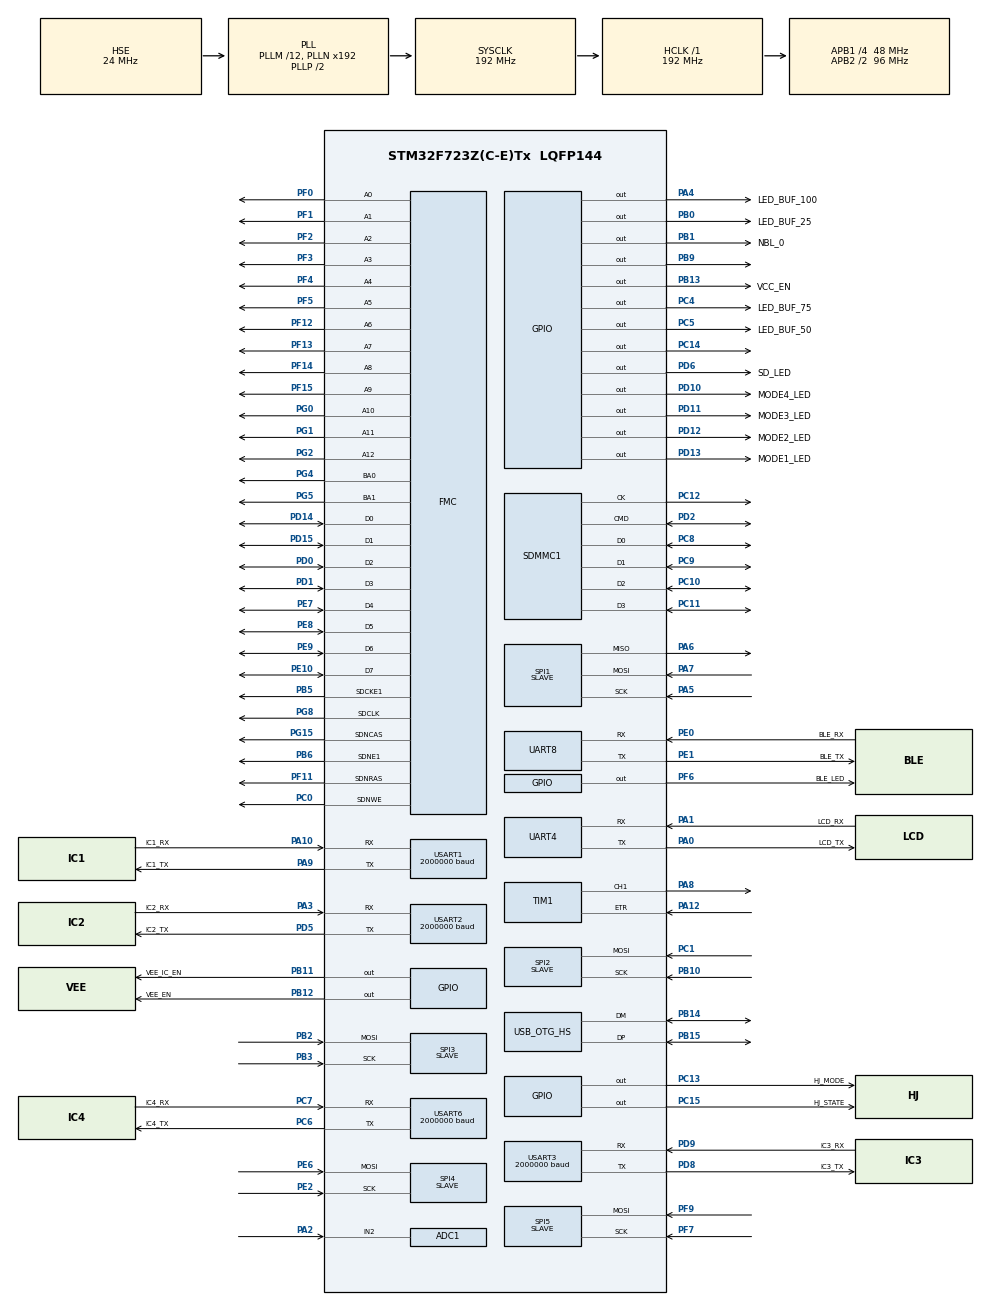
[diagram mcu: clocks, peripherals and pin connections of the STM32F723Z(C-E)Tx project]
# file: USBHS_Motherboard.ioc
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ADC1.Channel-0\#ChannelRegularConversion=ADC_CHANNEL_2
ADC1.ClockPrescaler=ADC_CLOCK_SYNC_PCLK_DIV4
ADC1.ContinuousConvMode=ENABLE
ADC1.DMAContinuousRequests=ENABLE
ADC1.DataAlign=ADC_DATAALIGN_LEFT
ADC1.EOCSelection=ADC_EOC_SINGLE_CONV
ADC1.ExternalTrigConv=ADC_SOFTWARE_START
ADC1.Mode=ADC_TRIPLEMODE_INTERL
ADC1.NbrOfConversion=1
ADC1.NbrOfConversionFlag=1
ADC1.Rank-0\#ChannelRegularConversion=1
ADC1.SamplingTime-0\#ChannelRegularConversion=ADC_SAMPLETIME_3CYCLES
ADC1.TwoSamplingDelay=ADC_TWOSAMPLINGDELAY_6CYCLES
ADC1.master=1
ADC2.Channel-0\#ChannelRegularConversion=ADC_CHANNEL_2
ADC2.ContinuousConvMode=DISABLE
ADC2.DMAAccessMode=ADC_DMAACCESSMODE_2
ADC2.DataAlign=ADC_DATAALIGN_LEFT
ADC2.Mode=ADC_TRIPLEMODE_INTERL
ADC2.NbrOfConversionFlag=1
ADC2.Rank-0\#ChannelRegularConversion=1
ADC2.SamplingTime-0\#ChannelRegularConversion=ADC_SAMPLETIME_3CYCLES
ADC2.TwoSamplingDelay=ADC_TWOSAMPLINGDELAY_6CYCLES
ADC3.Channel-0\#ChannelRegularConversion=ADC_CHANNEL_2
ADC3.ContinuousConvMode=DISABLE
ADC3.DMAAccessMode=ADC_DMAACCESSMODE_2
ADC3.DataAlign=ADC_DATAALIGN_LEFT
ADC3.Mode=ADC_TRIPLEMODE_INTERL
ADC3.NbrOfConversionFlag=1
ADC3.Rank-0\#ChannelRegularConversion=1
ADC3.SamplingTime-0\#ChannelRegularConversion=ADC_SAMPLETIME_3CYCLES
ADC3.TwoSamplingDelay=ADC_TWOSAMPLINGDELAY_6CYCLES
CORTEX_M7.ART_ACCLERATOR_ENABLE=0
CORTEX_M7.CPU_DCache=Enabled
CORTEX_M7.CPU_ICache=Enabled
CORTEX_M7.PREFETCH_ENABLE=1
Dma.ADC1.4.Direction=DMA_PERIPH_TO_MEMORY
Dma.ADC1.4.FIFOMode=DMA_FIFOMODE_ENABLE
Dma.ADC1.4.FIFOThreshold=DMA_FIFO_THRESHOLD_1QUARTERFULL
Dma.ADC1.4.Instance=DMA2_Stream0
Dma.ADC1.4.MemBurst=DMA_MBURST_SINGLE
Dma.ADC1.4.MemDataAlignment=DMA_MDATAALIGN_WORD
Dma.ADC1.4.MemInc=DMA_MINC_ENABLE
Dma.ADC1.4.Mode=DMA_CIRCULAR
Dma.ADC1.4.PeriphBurst=DMA_PBURST_SINGLE
Dma.ADC1.4.PeriphDataAlignment=DMA_PDATAALIGN_WORD
Dma.ADC1.4.PeriphInc=DMA_PINC_DISABLE
Dma.ADC1.4.Priority=DMA_PRIORITY_VERY_HIGH
Dma.Request0=USART1_RX
Dma.Request1=USART2_RX
Dma.Request2=USART3_RX
Dma.Request3=USART6_RX
Dma.Request4=ADC1
Dma.USART1_RX.0.Direction=DMA_PERIPH_TO_MEMORY
Dma.USART1_RX.0.FIFOMode=DMA_FIFOMODE_ENABLE
Dma.USART1_RX.0.FIFOThreshold=DMA_FIFO_THRESHOLD_HALFFULL
Dma.USART1_RX.0.Instance=DMA2_Stream2
Dma.USART1_RX.0.MemBurst=DMA_MBURST_SINGLE
Dma.USART1_RX.0.MemDataAlignment=DMA_MDATAALIGN_WORD
Dma.USART1_RX.0.MemInc=DMA_MINC_ENABLE
Dma.USART1_RX.0.Mode=DMA_NORMAL
Dma.USART1_RX.0.PeriphBurst=DMA_PBURST_SINGLE
Dma.USART1_RX.0.PeriphDataAlignment=DMA_PDATAALIGN_BYTE
Dma.USART1_RX.0.PeriphInc=DMA_PINC_DISABLE
Dma.USART1_RX.0.Priority=DMA_PRIORITY_MEDIUM
Dma.USART2_RX.1.Direction=DMA_PERIPH_TO_MEMORY
Dma.USART2_RX.1.FIFOMode=DMA_FIFOMODE_DISABLE
Dma.USART2_RX.1.Instance=DMA1_Stream5
Dma.USART2_RX.1.MemDataAlignment=DMA_MDATAALIGN_BYTE
Dma.USART2_RX.1.MemInc=DMA_MINC_ENABLE
Dma.USART2_RX.1.Mode=DMA_NORMAL
Dma.USART2_RX.1.PeriphDataAlignment=DMA_PDATAALIGN_BYTE
Dma.USART2_RX.1.PeriphInc=DMA_PINC_DISABLE
Dma.USART2_RX.1.Priority=DMA_PRIORITY_VERY_HIGH
Dma.USART3_RX.2.Direction=DMA_PERIPH_TO_MEMORY
Dma.USART3_RX.2.FIFOMode=DMA_FIFOMODE_ENABLE
Dma.USART3_RX.2.FIFOThreshold=DMA_FIFO_THRESHOLD_HALFFULL
Dma.USART3_RX.2.Instance=DMA1_Stream1
Dma.USART3_RX.2.MemBurst=DMA_MBURST_SINGLE
Dma.USART3_RX.2.MemDataAlignment=DMA_MDATAALIGN_WORD
Dma.USART3_RX.2.MemInc=DMA_MINC_ENABLE
Dma.USART3_RX.2.Mode=DMA_NORMAL
Dma.USART3_RX.2.PeriphBurst=DMA_PBURST_SINGLE
Dma.USART3_RX.2.PeriphDataAlignment=DMA_PDATAALIGN_WORD
Dma.USART3_RX.2.PeriphInc=DMA_PINC_DISABLE
Dma.USART3_RX.2.Priority=DMA_PRIORITY_LOW
Dma.USART6_RX.3.Direction=DMA_PERIPH_TO_MEMORY
Dma.USART6_RX.3.FIFOMode=DMA_FIFOMODE_ENABLE
Dma.USART6_RX.3.FIFOThreshold=DMA_FIFO_THRESHOLD_HALFFULL
Dma.USART6_RX.3.Instance=DMA2_Stream1
Dma.USART6_RX.3.MemBurst=DMA_MBURST_SINGLE
Dma.USART6_RX.3.MemDataAlignment=DMA_MDATAALIGN_WORD
Dma.USART6_RX.3.MemInc=DMA_MINC_ENABLE
Dma.USART6_RX.3.Mode=DMA_NORMAL
Dma.USART6_RX.3.PeriphBurst=DMA_PBURST_SINGLE
Dma.USART6_RX.3.PeriphDataAlignment=DMA_PDATAALIGN_WORD
Dma.USART6_RX.3.PeriphInc=DMA_PINC_DISABLE
Dma.USART6_RX.3.Priority=DMA_PRIORITY_LOW
FMC.CASLatency1=FMC_SDRAM_CAS_LATENCY_2
FMC.ColumnBitsNumber1=FMC_SDRAM_COLUMN_BITS_NUM_10
FMC.WriteProtection1=FMC_SDRAM_WRITE_PROTECTION_DISABLE
Mcu.Family=STM32F7
Mcu.Name=STM32F723Z(C-E)Tx
Mcu.Package=LQFP144
NVIC.DMA1_Stream1_IRQn=true\:1\:0\:true\:false\:true\:false\:false
NVIC.DMA1_Stream5_IRQn=true\:2\:0\:true\:false\:true\:false\:false
NVIC.DMA2_Stream0_IRQn=true\:2\:0\:true\:false\:true\:false\:false
NVIC.DMA2_Stream1_IRQn=true\:3\:0\:true\:false\:true\:false\:false
NVIC.DMA2_Stream2_IRQn=true\:4\:0\:true\:false\:true\:false\:false
NVIC.OTG_HS_IRQn=true\:5\:0\:true\:false\:true\:false\:true
NVIC.PriorityGroup=NVIC_PRIORITYGROUP_4
NVIC.SDMMC1_IRQn=true\:9\:0\:true\:false\:true\:true\:false
NVIC.TIM8_TRG_COM_TIM14_IRQn=true\:6\:0\:true\:false\:true\:true\:false
NVIC.UART4_IRQn=true\:11\:0\:true\:false\:true\:true\:false
NVIC.UART8_IRQn=true\:15\:0\:true\:false\:true\:true\:false
NVIC.USART1_IRQn=true\:12\:0\:true\:false\:true\:true\:false
NVIC.USART2_IRQn=true\:13\:0\:true\:false\:true\:true\:false
NVIC.USART3_IRQn=true\:14\:0\:true\:false\:true\:true\:false
NVIC.USART6_IRQn=true\:10\:0\:true\:false\:true\:true\:false
PA0-WKUP.GPIO_Label=LCD_TX
PA0-WKUP.Mode=Asynchronous
PA0-WKUP.Signal=UART4_TX
PA1.GPIO_Label=LCD_RX
PA1.Mode=Asynchronous
PA1.Signal=UART4_RX
PA10.GPIO_Label=IC1_RX
PA10.Mode=Asynchronous
PA10.Signal=USART1_RX
PA12.Signal=S_TIM1_ETR
PA13.Mode=Serial_Wire
PA13.Signal=SYS_JTMS-SWDIO
PA14.Mode=Serial_Wire
PA14.Signal=SYS_JTCK-SWCLK
PA2.Signal=ADCx_IN2
PA3.GPIO_Label=IC2_RX
PA3.Mode=Asynchronous
PA3.Signal=USART2_RX
PA4.GPIO_Label=LED_BUF_100
PA4.Signal=GPIO_Output
PA5.Mode=Full_Duplex_Slave
PA5.Signal=SPI1_SCK
PA6.Mode=Full_Duplex_Slave
PA6.Signal=SPI1_MISO
PA7.Mode=Full_Duplex_Slave
PA7.Signal=SPI1_MOSI
PA8.Signal=S_TIM1_CH1
PA9.GPIO_Label=IC1_TX
PA9.Mode=Asynchronous
PA9.Signal=USART1_TX
PB0.GPIO_Label=LED_BUF_25
PB0.Signal=GPIO_Output
PB1.GPIO_Label=NBL_0
PB1.GPIO_Speed=GPIO_SPEED_FREQ_VERY_HIGH
PB1.PinState=GPIO_PIN_SET
PB1.Signal=GPIO_Output
PB10.Mode=RX_Only_Simplex_Unidirect_Slave
PB10.Signal=SPI2_SCK
PB11.GPIO_Label=VEE_IC_EN
PB11.Signal=GPIO_Output
PB12.GPIO_Label=VEE_EN
PB12.Signal=GPIO_Output
PB13.GPIO_Label=VCC_EN
PB13.Signal=GPIO_Output
PB14.Mode=Internal_Phy_Device
PB14.Signal=USB_OTG_HS_DM
PB15.Mode=Internal_Phy_Device
PB15.Signal=USB_OTG_HS_DP
PB2.Mode=RX_Only_Simplex_Unidirect_Slave
PB2.Signal=SPI3_MOSI
PB3.Mode=RX_Only_Simplex_Unidirect_Slave
PB3.Signal=SPI3_SCK
PB5.Mode=SdramChipSelect2_1
PB5.Signal=FMC_SDCKE1
PB6.Mode=SdramChipSelect2_1
PB6.Signal=FMC_SDNE1
PB9.Signal=GPIO_Output
PC0.Signal=FMC_SDNWE
PC1.Mode=RX_Only_Simplex_Unidirect_Slave
PC1.Signal=SPI2_MOSI
PC10.Mode=SD_4_bits_Wide_bus
PC10.Signal=SDMMC1_D2
PC11.Mode=SD_4_bits_Wide_bus
PC11.Signal=SDMMC1_D3
PC12.Mode=SD_4_bits_Wide_bus
PC12.Signal=SDMMC1_CK
PC13.GPIO_Label=HJ_MODE
PC13.Signal=GPIO_Output
PC14-OSC32_IN.Signal=GPIO_Output
PC15-OSC32_OUT.GPIO_Label=HJ_STATE
PC15-OSC32_OUT.Signal=GPIO_Output
PC4.GPIO_Label=LED_BUF_75
PC4.Signal=GPIO_Output
PC5.GPIO_Label=LED_BUF_50
PC5.Signal=GPIO_Output
PC6.GPIO_Label=IC4_TX
PC6.Mode=Asynchronous
PC6.Signal=USART6_TX
PC7.GPIO_Label=IC4_RX
PC7.Mode=Asynchronous
PC7.Signal=USART6_RX
PC8.Mode=SD_4_bits_Wide_bus
PC8.Signal=SDMMC1_D0
PC9.Mode=SD_4_bits_Wide_bus
PC9.Signal=SDMMC1_D1
PD0.Signal=FMC_D2_DA2
PD1.Signal=FMC_D3_DA3
PD10.GPIO_Label=MODE4_LED
PD10.Signal=GPIO_Output
PD11.GPIO_Label=MODE3_LED
PD11.Signal=GPIO_Output
PD12.GPIO_Label=MODE2_LED
PD12.Signal=GPIO_Output
PD13.GPIO_Label=MODE1_LED
PD13.Signal=GPIO_Output
PD14.Signal=FMC_D0_DA0
PD15.Signal=FMC_D1_DA1
PD2.Mode=SD_4_bits_Wide_bus
PD2.Signal=SDMMC1_CMD
PD5.GPIO_Label=IC2_TX
PD5.Mode=Asynchronous
PD5.Signal=USART2_TX
PD6.GPIO_Label=SD_LED
PD6.Signal=GPIO_Output
PD8.GPIO_Label=IC3_TX
PD8.Mode=Asynchronous
PD8.Signal=USART3_TX
PD9.GPIO_Label=IC3_RX
PD9.Mode=Asynchronous
PD9.Signal=USART3_RX
PE0.GPIO_Label=BLE_RX
PE0.Mode=Asynchronous
PE0.Signal=UART8_RX
PE1.GPIO_Label=BLE_TX
PE1.Mode=Asynchronous
PE1.Signal=UART8_TX
PE10.Signal=FMC_D7_DA7
PE2.Mode=RX_Only_Simplex_Unidirect_Slave
PE2.Signal=SPI4_SCK
PE6.Mode=RX_Only_Simplex_Unidirect_Slave
PE6.Signal=SPI4_MOSI
PE7.Signal=FMC_D4_DA4
PE8.Signal=FMC_D5_DA5
PE9.Signal=FMC_D6_DA6
PF0.Signal=FMC_A0
PF1.Signal=FMC_A1
PF11.Signal=FMC_SDNRAS
PF12.Signal=FMC_A6
PF13.Signal=FMC_A7
PF14.Signal=FMC_A8
PF15.Signal=FMC_A9
PF2.Signal=FMC_A2
PF3.Signal=FMC_A3
PF4.Signal=FMC_A4
PF5.Signal=FMC_A5
PF6.GPIO_Label=BLE_LED
PF6.Signal=GPIO_Output
PF7.Mode=RX_Only_Simplex_Unidirect_Slave
PF7.Signal=SPI5_SCK
PF9.Mode=RX_Only_Simplex_Unidirect_Slave
PF9.Signal=SPI5_MOSI
PG0.Signal=FMC_A10
PG1.Signal=FMC_A11
PG15.Signal=FMC_SDNCAS
PG2.Signal=FMC_A12
PG4.Signal=FMC_A14_BA0
PG5.Signal=FMC_A15_BA1
PG8.Signal=FMC_SDCLK
PH0-OSC_IN.Mode=HSE-External-Oscillator
PH0-OSC_IN.Signal=RCC_OSC_IN
PH1-OSC_OUT.Mode=HSE-External-Oscillator
PH1-OSC_OUT.Signal=RCC_OSC_OUT
ProjectManager.HeapSize=0x2000
ProjectManager.StackSize=0x2000
ProjectManager.TargetToolchain=MDK-ARM V5
RCC.AHBFreq_Value=192000000
RCC.APB1CLKDivider=RCC_HCLK_DIV4
RCC.APB1Freq_Value=48000000
RCC.APB1TimFreq_Value=96000000
RCC.APB2CLKDivider=RCC_HCLK_DIV2
RCC.APB2Freq_Value=96000000
RCC.APB2TimFreq_Value=192000000
RCC.CortexFreq_Value=192000000
RCC.HCLKFreq_Value=192000000
RCC.HSE_VALUE=24000000
RCC.HSI_VALUE=16000000
RCC.LSE_VALUE=32768
RCC.PLLM=12
RCC.PLLQ=8
RCC.SDMMCClockSelection=RCC_SDMMC1CLKSOURCE_CLK48
RCC.SYSCLKFreq_VALUE=192000000
RCC.SYSCLKSource=RCC_SYSCLKSOURCE_PLLCLK
RCC.USBFreq_Value=48000000
RCC.VCOOutputFreq_Value=384000000
REXTPHYHS.Mode=Internal_Phy_Device
REXTPHYHS.Signal=USB_OTG_HS_REXTPHYHS
SH.ADCx_IN2.0=ADC1_IN2,IN2
SH.ADCx_IN2.1=ADC2_IN2,IN2
SH.ADCx_IN2.2=ADC3_IN2,IN2
SH.FMC_A0.0=FMC_A0,13b-sda1
SH.FMC_A1.0=FMC_A1,13b-sda1
SH.FMC_A10.0=FMC_A10,13b-sda1
SH.FMC_A11.0=FMC_A11,13b-sda1
SH.FMC_A12.0=FMC_A12,13b-sda1
SH.FMC_A14_BA0.0=FMC_BA0,FourSdramBanks1
SH.FMC_A15_BA1.0=FMC_BA1,FourSdramBanks1
SH.FMC_A2.0=FMC_A2,13b-sda1
SH.FMC_A3.0=FMC_A3,13b-sda1
SH.FMC_A4.0=FMC_A4,13b-sda1
SH.FMC_A5.0=FMC_A5,13b-sda1
SH.FMC_A6.0=FMC_A6,13b-sda1
SH.FMC_A7.0=FMC_A7,13b-sda1
SH.FMC_A8.0=FMC_A8,13b-sda1
SH.FMC_A9.0=FMC_A9,13b-sda1
SH.FMC_D0_DA0.0=FMC_D0,sd-8b-d1
SH.FMC_D1_DA1.0=FMC_D1,sd-8b-d1
SH.FMC_D2_DA2.0=FMC_D2,sd-8b-d1
SH.FMC_D3_DA3.0=FMC_D3,sd-8b-d1
SH.FMC_D4_DA4.0=FMC_D4,sd-8b-d1
SH.FMC_D5_DA5.0=FMC_D5,sd-8b-d1
SH.FMC_D6_DA6.0=FMC_D6,sd-8b-d1
SH.FMC_D7_DA7.0=FMC_D7,sd-8b-d1
SH.FMC_SDCLK.0=FMC_SDCLK,13b-sda1
SH.FMC_SDNCAS.0=FMC_SDNCAS,13b-sda1
SH.FMC_SDNRAS.0=FMC_SDNRAS,13b-sda1
SH.FMC_SDNWE.0=FMC_SDNWE,13b-sda1
SH.S_TIM1_CH1.0=TIM1_CH1,Output Compare1 CH1
SH.S_TIM1_ETR.0=TIM1_ETR,TriggerSource_ETR
SPI1.DataSize=SPI_DATASIZE_16BIT
SPI1.Direction=SPI_DIRECTION_2LINES
SPI1.Mode=SPI_MODE_SLAVE
SPI1.VirtualType=VM_SLAVE
SPI2.DataSize=SPI_DATASIZE_16BIT
SPI2.Direction=SPI_DIRECTION_2LINES_RXONLY
SPI2.Mode=SPI_MODE_SLAVE
SPI2.VirtualType=VM_SLAVE
SPI3.DataSize=SPI_DATASIZE_16BIT
SPI3.Direction=SPI_DIRECTION_2LINES_RXONLY
SPI3.Mode=SPI_MODE_SLAVE
SPI3.VirtualType=VM_SLAVE
SPI4.DataSize=SPI_DATASIZE_16BIT
SPI4.Direction=SPI_DIRECTION_2LINES_RXONLY
SPI4.Mode=SPI_MODE_SLAVE
SPI4.VirtualType=VM_SLAVE
SPI5.DataSize=SPI_DATASIZE_16BIT
SPI5.Direction=SPI_DIRECTION_2LINES_RXONLY
SPI5.Mode=SPI_MODE_SLAVE
SPI5.VirtualType=VM_SLAVE
TIM1.Channel-Output\ Compare1\ CH1=TIM_CHANNEL_1
TIM14.AutoReloadPreload=TIM_AUTORELOAD_PRELOAD_ENABLE
TIM14.Period=1999
TIM14.Prescaler=21599
TIM6.AutoReloadPreload=TIM_AUTORELOAD_PRELOAD_ENABLE
TIM6.Period=143
TIM6.Prescaler=0
TIM6.TIM_MasterOutputTrigger=TIM_TRGO_UPDATE
USART1.BaudRate=2000000
USART1.DMADisableonRxErrorParam=ADVFEATURE_DMA_ENABLEONRXERROR
USART1.OverSampling=UART_OVERSAMPLING_16
USART1.OverrunDisableParam=ADVFEATURE_OVERRUN_DISABLE
USART1.VirtualMode-Asynchronous=VM_ASYNC
USART2.BaudRate=2000000
USART2.DMADisableonRxErrorParam=ADVFEATURE_DMA_ENABLEONRXERROR
USART2.OverSampling=UART_OVERSAMPLING_16
USART2.OverrunDisableParam=ADVFEATURE_OVERRUN_DISABLE
USART2.VirtualMode-Asynchronous=VM_ASYNC
USART3.BaudRate=2000000
USART3.DMADisableonRxErrorParam=ADVFEATURE_DMA_ENABLEONRXERROR
USART3.OverSampling=UART_OVERSAMPLING_16
USART3.OverrunDisableParam=ADVFEATURE_OVERRUN_DISABLE
USART3.VirtualMode-Asynchronous=VM_ASYNC
USART6.BaudRate=2000000
USART6.DMADisableonRxErrorParam=ADVFEATURE_DMA_ENABLEONRXERROR
USART6.OverSampling=UART_OVERSAMPLING_16
USART6.OverrunDisableParam=ADVFEATURE_OVERRUN_DISABLE
USART6.VirtualMode-Asynchronous=VM_ASYNC
USB_DEVICE.CLASS_NAME_HS=CDC
USB_DEVICE.USBD_LPM_ENABLED-CDC_HS=0
USB_DEVICE.USBD_SELF_POWERED-CDC_HS=1
USB_DEVICE.VirtualMode-CDC_HS=Cdc
USB_DEVICE.VirtualModeHS=Cdc_HS
USB_OTG_HS.VirtualMode=Int_Phy_Device
VP_TIM14_VS_ClockSourceINT.Mode=Enable_Timer
VP_TIM1_VS_ClockSourceINT.Mode=Internal
VP_TIM1_VS_ControllerModeTrigger.Mode=Trigger Mode
VP_TIM6_VS_ClockSourceINT.Mode=Enable_Timer
VP_USB_DEVICE_VS_USB_DEVICE_CDC_HS.Mode=CDC_HS
board=custom

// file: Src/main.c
/* USER CODE BEGIN Header */
/**
  ******************************************************************************
  * @file           : main.c
  * @brief          : Main program body
  ******************************************************************************
  * @attention
  *
  * <h2><center>&copy; Copyright (c) 2020 STMicroelectronics.
  * All rights reserved.</center></h2>
  *
  * This software component is licensed by ST under Ultimate Liberty license
  * SLA0044, the "License"; You may not use this file except in compliance with
  * the License. You may obtain a copy of the License at:
  *                             www.st.com/SLA0044
  *
  ******************************************************************************
  */
/* USER CODE END Header */

#include "main.h"
#include "usb_device.h"

/* USER CODE BEGIN Includes */
#include "dataMGR.h"
#include "CE32_ioncom.h"
#include "usbd_cdc_if.h"

/* USER CODE END Includes */

ADC_HandleTypeDef hadc1;
ADC_HandleTypeDef hadc2;
ADC_HandleTypeDef hadc3;
DMA_HandleTypeDef hdma_adc1;

SD_HandleTypeDef hsd1;

SPI_HandleTypeDef hspi1;
SPI_HandleTypeDef hspi2;
SPI_HandleTypeDef hspi3;
SPI_HandleTypeDef hspi4;
SPI_HandleTypeDef hspi5;

TIM_HandleTypeDef htim1;
TIM_HandleTypeDef htim6;
TIM_HandleTypeDef htim14;

UART_HandleTypeDef huart4;
UART_HandleTypeDef huart8;
UART_HandleTypeDef huart1;
UART_HandleTypeDef huart2;
UART_HandleTypeDef huart3;
UART_HandleTypeDef huart6;
DMA_HandleTypeDef hdma_usart1_rx;
DMA_HandleTypeDef hdma_usart2_rx;
DMA_HandleTypeDef hdma_usart3_rx;
DMA_HandleTypeDef hdma_usart6_rx;

SDRAM_HandleTypeDef hsdram1;

/* USER CODE BEGIN PV */
int Nfail;
int retries;
int WaitCyc;
uint8_t data_buf_RX1[0x10];		// This records @ 20kHz x 32CH
uint8_t data_buf_RX2[0x10];		// This records @ 20kHz x 32CH
uint8_t data_buf_RX3[0x10];		// This records @ 20kHz x 32CH
uint8_t data_buf_RX4[0x10];		// This records @ 20kHz x 32CH
uint8_t data_buf_TX[0x100];		// This records @ 20kHz x 32CH
uint8_t data_buf_RX_CDC[BUF_SIZE];
uint16_t misc_DigiSig;
uint8_t rec_cnt;
uint32_t log_cnt;
uint32_t test;
uint32_t LED_CNT;
uint32_t logIdx;	//Index of log in the CE32_systemLog struct
uint32_t filePTR;	//recording pointer location (in 512B unit,real filelen=512*x)
uint32_t updHeader;
dataMGR MGR_TX;
dataMGR MGR_RX1;
dataMGR MGR_RX2;
dataMGR MGR_RX3;
dataMGR MGR_RX4;
dataMGR MGR_CDC;
dataMGR MGR_prev;
dataMGR MGR_misc;
dataMGR MGR_cmd;
uint8_t HD32_sd_temp;

//dataMGR PMGR;
int freq;

const uint16_t RX_size=1000;

CE32_IONCOM_Handle IC_handle1;
CE32_IONCOM_Handle IC_handle2;
CE32_IONCOM_Handle IC_handle3;
CE32_IONCOM_Handle IC_handle4;

extern USBD_HandleTypeDef hUsbDeviceFS;

/* USER CODE END PV */

void SystemClock_Config(void);
static void MX_GPIO_Init(void);
static void MX_DMA_Init(void);
static void MX_FMC_Init(void);
static void MX_SDMMC1_SD_Init(void);
static void MX_SPI1_Init(void);
static void MX_SPI2_Init(void);
static void MX_SPI3_Init(void);
static void MX_SPI4_Init(void);
static void MX_SPI5_Init(void);
static void MX_TIM1_Init(void);
static void MX_UART4_Init(void);
static void MX_UART8_Init(void);
static void MX_USART1_UART_Init(void);
static void MX_USART2_UART_Init(void);
static void MX_USART3_UART_Init(void);
static void MX_USART6_UART_Init(void);
static void MX_TIM14_Init(void);
static void MX_ADC1_Init(void);
static void MX_ADC2_Init(void);
static void MX_ADC3_Init(void);
static void MX_TIM6_Init(void);
/* USER CODE BEGIN PFP */

void PowerUp_IC();
void Init_Buffer();
void Init_Ioncom_Receiver();
void RXdata_Indicator_Init();
void RX_processor(CE32_IONCOM_Handle *IC_handle,int CH);
void USB_SEND();
/* USER CODE END PFP */

int main(void)
{

  /* Enable I-Cache---------------------------------------------------------*/
  SCB_EnableICache();

  /* Enable D-Cache---------------------------------------------------------*/
  SCB_EnableDCache();

  /* MCU Configuration--------------------------------------------------------*/

  /* Reset of all peripherals, Initializes the Flash interface and the Systick. */
  HAL_Init();

  /* Configure the system clock */
  SystemClock_Config();

  /* Initialize all configured peripherals */
  MX_GPIO_Init();
  MX_DMA_Init();
  MX_FMC_Init();
  MX_SDMMC1_SD_Init();
  MX_SPI1_Init();
  MX_SPI2_Init();
  MX_SPI3_Init();
  MX_SPI4_Init();
  MX_SPI5_Init();
  MX_TIM1_Init();
  MX_UART4_Init();
  MX_UART8_Init();
  MX_USART1_UART_Init();
  MX_USART2_UART_Init();
  MX_USART3_UART_Init();
  MX_USART6_UART_Init();
  MX_USB_DEVICE_Init();
  MX_TIM14_Init();
  MX_ADC1_Init();
  MX_ADC2_Init();
  MX_ADC3_Init();
  MX_TIM6_Init();
  /* USER CODE BEGIN 2 */
	//PowerUp_IC();
	//HAL_PWR_EnterSTOPMode(PWR_LOWPOWERREGULATOR_ON,PWR_STOPENTRY_WFI); //Enter STOP mode for debug
	Init_Buffer();
	//Init_Ioncom_Receiver();
	//MX_USB_DEVICE_Init();
	//RXdata_Indicator_Init();
	__HAL_ADC_ENABLE(&hadc1);
	__HAL_ADC_ENABLE(&hadc2);
	__HAL_ADC_ENABLE(&hadc3);
	uint32_t * ADC_test;
	//HAL_ADCEx_MultiModeStart_DMA(&hadc1,(uint32_t*)ADC_test,1);
	HAL_ADCEx_MultiModeStart_DMA(&hadc1,(uint32_t*)&data_buf_RX_CDC[3],(BUF_SIZE/4));
	__HAL_DMA_DISABLE_IT(hadc1.DMA_Handle,DMA_IT_TE); //disable interrupts other than half/full complete
	//__HAL_DMA_DISABLE_IT(hadc1.DMA_Handle,DMA_IT_FE);
	__HAL_DMA_DISABLE_IT(hadc1.DMA_Handle,DMA_IT_DME);
	hadc1.Instance->CR2 |= (uint32_t)ADC_CR2_SWSTART;
	//HAL_TIM_Base_Start(&htim6);// start timer for ADC
//	uint16_t x=0;
//	for(uint32_t i=0;i<BUF_SIZE/2;i++)
//	{
//		uint16_t* ptr =	(uint16_t*)data_buf_RX_CDC;
//		ptr[i] = 1000;
//	}
  /* USER CODE END 2 */

  /* Infinite loop */
  while (1)
  {

    /* USER CODE BEGIN 3 */
		//RX_processor(&IC_handle1,0);
		//RX_processor(&IC_handle2,1);
		//RX_processor(&IC_handle3,2);
		//RX_processor(&IC_handle4,3);
		HAL_GPIO_WritePin(LED_BUF_25_GPIO_Port,LED_BUF_25_Pin,MGR_CDC.bufferUsed[0]>(BUF_SIZE/4)?1:0);
		HAL_GPIO_WritePin(LED_BUF_50_GPIO_Port,LED_BUF_50_Pin,MGR_CDC.bufferUsed[0]>(BUF_SIZE/2)?1:0);
		HAL_GPIO_WritePin(LED_BUF_75_GPIO_Port,LED_BUF_75_Pin,MGR_CDC.bufferUsed[0]>(BUF_SIZE*3/4)?1:0);
		HAL_GPIO_WritePin(LED_BUF_100_GPIO_Port,LED_BUF_100_Pin,MGR_CDC.bufferUsed[0]>=BUF_SIZE?1:0);

		if(MGR_CDC.bufferUsed[0]>2*BUF_SIZE)
		{
			uint32_t purge_cnt=BUF_SIZE/2;
			dataMGR_deQueue(&MGR_CDC,purge_cnt,0); //clear buffer
		}
		USB_SEND();
//		if(MGR_CDC.bufferUsed[0]<BUF_SIZE/2)
//		{
//			dataMGR_enQueue_Nbytes(&MGR_CDC,BUF_SIZE/2);
//		}
  }
  /* USER CODE END 3 */
}

void SystemClock_Config(void)
{
  RCC_OscInitTypeDef RCC_OscInitStruct = {0};
  RCC_ClkInitTypeDef RCC_ClkInitStruct = {0};
  RCC_PeriphCLKInitTypeDef PeriphClkInitStruct = {0};

  /** Configure the main internal regulator output voltage
  */
  __HAL_RCC_PWR_CLK_ENABLE();
  __HAL_PWR_VOLTAGESCALING_CONFIG(PWR_REGULATOR_VOLTAGE_SCALE1);
  /** Initializes the CPU, AHB and APB busses clocks
  */
  RCC_OscInitStruct.OscillatorType = RCC_OSCILLATORTYPE_HSE;
  RCC_OscInitStruct.HSEState = RCC_HSE_ON;
  RCC_OscInitStruct.PLL.PLLState = RCC_PLL_ON;
  RCC_OscInitStruct.PLL.PLLSource = RCC_PLLSOURCE_HSE;
  RCC_OscInitStruct.PLL.PLLM = 12;
  RCC_OscInitStruct.PLL.PLLN = 192;
  RCC_OscInitStruct.PLL.PLLP = RCC_PLLP_DIV2;
  RCC_OscInitStruct.PLL.PLLQ = 8;
  if (HAL_RCC_OscConfig(&RCC_OscInitStruct) != HAL_OK)
  {
    Error_Handler();
  }
  /** Activate the Over-Drive mode
  */
  if (HAL_PWREx_EnableOverDrive() != HAL_OK)
  {
    Error_Handler();
  }
  /** Initializes the CPU, AHB and APB busses clocks
  */
  RCC_ClkInitStruct.ClockType = RCC_CLOCKTYPE_HCLK|RCC_CLOCKTYPE_SYSCLK
                              |RCC_CLOCKTYPE_PCLK1|RCC_CLOCKTYPE_PCLK2;
  RCC_ClkInitStruct.SYSCLKSource = RCC_SYSCLKSOURCE_PLLCLK;
  RCC_ClkInitStruct.AHBCLKDivider = RCC_SYSCLK_DIV1;
  RCC_ClkInitStruct.APB1CLKDivider = RCC_HCLK_DIV4;
  RCC_ClkInitStruct.APB2CLKDivider = RCC_HCLK_DIV2;

  if (HAL_RCC_ClockConfig(&RCC_ClkInitStruct, FLASH_LATENCY_6) != HAL_OK)
  {
    Error_Handler();
  }
  PeriphClkInitStruct.PeriphClockSelection = RCC_PERIPHCLK_USART1|RCC_PERIPHCLK_USART2
                              |RCC_PERIPHCLK_USART3|RCC_PERIPHCLK_USART6
                              |RCC_PERIPHCLK_UART4|RCC_PERIPHCLK_UART8
                              |RCC_PERIPHCLK_SDMMC1|RCC_PERIPHCLK_CLK48;
  PeriphClkInitStruct.Usart1ClockSelection = RCC_USART1CLKSOURCE_PCLK2;
  PeriphClkInitStruct.Usart2ClockSelection = RCC_USART2CLKSOURCE_PCLK1;
  PeriphClkInitStruct.Usart3ClockSelection = RCC_USART3CLKSOURCE_PCLK1;
  PeriphClkInitStruct.Uart4ClockSelection = RCC_UART4CLKSOURCE_PCLK1;
  PeriphClkInitStruct.Usart6ClockSelection = RCC_USART6CLKSOURCE_PCLK2;
  PeriphClkInitStruct.Uart8ClockSelection = RCC_UART8CLKSOURCE_PCLK1;
  PeriphClkInitStruct.Clk48ClockSelection = RCC_CLK48SOURCE_PLL;
  PeriphClkInitStruct.Sdmmc1ClockSelection = RCC_SDMMC1CLKSOURCE_CLK48;
  if (HAL_RCCEx_PeriphCLKConfig(&PeriphClkInitStruct) != HAL_OK)
  {
    Error_Handler();
  }
}

static void MX_ADC1_Init(void)
{

  ADC_MultiModeTypeDef multimode = {0};
  ADC_ChannelConfTypeDef sConfig = {0};

  /** Configure the global features of the ADC (Clock, Resolution, Data Alignment and number of conversion)
  */
  hadc1.Instance = ADC1;
  hadc1.Init.ClockPrescaler = ADC_CLOCK_SYNC_PCLK_DIV4;
  hadc1.Init.Resolution = ADC_RESOLUTION_12B;
  hadc1.Init.ScanConvMode = ADC_SCAN_DISABLE;
  hadc1.Init.ContinuousConvMode = ENABLE;
  hadc1.Init.DiscontinuousConvMode = DISABLE;
  hadc1.Init.ExternalTrigConvEdge = ADC_EXTERNALTRIGCONVEDGE_NONE;
  hadc1.Init.ExternalTrigConv = ADC_SOFTWARE_START;
  hadc1.Init.DataAlign = ADC_DATAALIGN_LEFT;
  hadc1.Init.NbrOfConversion = 1;
  hadc1.Init.DMAContinuousRequests = ENABLE;
  hadc1.Init.EOCSelection = ADC_EOC_SINGLE_CONV;
  if (HAL_ADC_Init(&hadc1) != HAL_OK)
  {
    Error_Handler();
  }
  /** Configure the ADC multi-mode
  */
  multimode.Mode = ADC_TRIPLEMODE_INTERL;
  multimode.DMAAccessMode = ADC_DMAACCESSMODE_2;
  multimode.TwoSamplingDelay = ADC_TWOSAMPLINGDELAY_6CYCLES;
  if (HAL_ADCEx_MultiModeConfigChannel(&hadc1, &multimode) != HAL_OK)
  {
    Error_Handler();
  }
  /** Configure for the selected ADC regular channel its corresponding rank in the sequencer and its sample time.
  */
  sConfig.Channel = ADC_CHANNEL_2;
  sConfig.Rank = ADC_REGULAR_RANK_1;
  sConfig.SamplingTime = ADC_SAMPLETIME_3CYCLES;
  if (HAL_ADC_ConfigChannel(&hadc1, &sConfig) != HAL_OK)
  {
    Error_Handler();
  }

}

static void MX_ADC2_Init(void)
{

  ADC_ChannelConfTypeDef sConfig = {0};

  /** Configure the global features of the ADC (Clock, Resolution, Data Alignment and number of conversion)
  */
  hadc2.Instance = ADC2;
  hadc2.Init.ClockPrescaler = ADC_CLOCK_SYNC_PCLK_DIV4;
  hadc2.Init.Resolution = ADC_RESOLUTION_12B;
  hadc2.Init.ScanConvMode = ADC_SCAN_DISABLE;
  hadc2.Init.ContinuousConvMode = DISABLE;
  hadc2.Init.DiscontinuousConvMode = DISABLE;
  hadc2.Init.DataAlign = ADC_DATAALIGN_LEFT;
  hadc2.Init.NbrOfConversion = 1;
  hadc2.Init.DMAContinuousRequests = DISABLE;
  hadc2.Init.EOCSelection = ADC_EOC_SINGLE_CONV;
  if (HAL_ADC_Init(&hadc2) != HAL_OK)
  {
    Error_Handler();
  }
  /** Configure for the selected ADC regular channel its corresponding rank in the sequencer and its sample time.
  */
  sConfig.Channel = ADC_CHANNEL_2;
  sConfig.Rank = ADC_REGULAR_RANK_1;
  sConfig.SamplingTime = ADC_SAMPLETIME_3CYCLES;
  if (HAL_ADC_ConfigChannel(&hadc2, &sConfig) != HAL_OK)
  {
    Error_Handler();
  }

}

static void MX_ADC3_Init(void)
{

  ADC_ChannelConfTypeDef sConfig = {0};

  /** Configure the global features of the ADC (Clock, Resolution, Data Alignment and number of conversion)
  */
  hadc3.Instance = ADC3;
  hadc3.Init.ClockPrescaler = ADC_CLOCK_SYNC_PCLK_DIV4;
  hadc3.Init.Resolution = ADC_RESOLUTION_12B;
  hadc3.Init.ScanConvMode = ADC_SCAN_DISABLE;
  hadc3.Init.ContinuousConvMode = DISABLE;
  hadc3.Init.DiscontinuousConvMode = DISABLE;
  hadc3.Init.DataAlign = ADC_DATAALIGN_LEFT;
  hadc3.Init.NbrOfConversion = 1;
  hadc3.Init.DMAContinuousRequests = DISABLE;
  hadc3.Init.EOCSelection = ADC_EOC_SINGLE_CONV;
  if (HAL_ADC_Init(&hadc3) != HAL_OK)
  {
    Error_Handler();
  }
  /** Configure for the selected ADC regular channel its corresponding rank in the sequencer and its sample time.
  */
  sConfig.Channel = ADC_CHANNEL_2;
  sConfig.Rank = ADC_REGULAR_RANK_1;
  sConfig.SamplingTime = ADC_SAMPLETIME_3CYCLES;
  if (HAL_ADC_ConfigChannel(&hadc3, &sConfig) != HAL_OK)
  {
    Error_Handler();
  }

}

static void MX_SDMMC1_SD_Init(void)
{

  hsd1.Instance = SDMMC1;
  hsd1.Init.ClockEdge = SDMMC_CLOCK_EDGE_RISING;
  hsd1.Init.ClockBypass = SDMMC_CLOCK_BYPASS_DISABLE;
  hsd1.Init.ClockPowerSave = SDMMC_CLOCK_POWER_SAVE_DISABLE;
  hsd1.Init.BusWide = SDMMC_BUS_WIDE_1B;
  hsd1.Init.HardwareFlowControl = SDMMC_HARDWARE_FLOW_CONTROL_DISABLE;
  hsd1.Init.ClockDiv = 0;
  if (HAL_SD_Init(&hsd1) != HAL_OK)
  {
    Error_Handler();
  }
  if (HAL_SD_ConfigWideBusOperation(&hsd1, SDMMC_BUS_WIDE_4B) != HAL_OK)
  {
    Error_Handler();
  }

}

static void MX_SPI1_Init(void)
{

  /* SPI1 parameter configuration*/
  hspi1.Instance = SPI1;
  hspi1.Init.Mode = SPI_MODE_SLAVE;
  hspi1.Init.Direction = SPI_DIRECTION_2LINES;
  hspi1.Init.DataSize = SPI_DATASIZE_16BIT;
  hspi1.Init.CLKPolarity = SPI_POLARITY_LOW;
  hspi1.Init.CLKPhase = SPI_PHASE_1EDGE;
  hspi1.Init.NSS = SPI_NSS_SOFT;
  hspi1.Init.FirstBit = SPI_FIRSTBIT_MSB;
  hspi1.Init.TIMode = SPI_TIMODE_DISABLE;
  hspi1.Init.CRCCalculation = SPI_CRCCALCULATION_DISABLE;
  hspi1.Init.CRCPolynomial = 7;
  hspi1.Init.CRCLength = SPI_CRC_LENGTH_DATASIZE;
  hspi1.Init.NSSPMode = SPI_NSS_PULSE_DISABLE;
  if (HAL_SPI_Init(&hspi1) != HAL_OK)
  {
    Error_Handler();
  }

}

static void MX_SPI2_Init(void)
{

  /* SPI2 parameter configuration*/
  hspi2.Instance = SPI2;
  hspi2.Init.Mode = SPI_MODE_SLAVE;
  hspi2.Init.Direction = SPI_DIRECTION_2LINES_RXONLY;
  hspi2.Init.DataSize = SPI_DATASIZE_16BIT;
  hspi2.Init.CLKPolarity = SPI_POLARITY_LOW;
  hspi2.Init.CLKPhase = SPI_PHASE_1EDGE;
  hspi2.Init.NSS = SPI_NSS_SOFT;
  hspi2.Init.FirstBit = SPI_FIRSTBIT_MSB;
  hspi2.Init.TIMode = SPI_TIMODE_DISABLE;
  hspi2.Init.CRCCalculation = SPI_CRCCALCULATION_DISABLE;
  hspi2.Init.CRCPolynomial = 7;
  hspi2.Init.CRCLength = SPI_CRC_LENGTH_DATASIZE;
  hspi2.Init.NSSPMode = SPI_NSS_PULSE_DISABLE;
  if (HAL_SPI_Init(&hspi2) != HAL_OK)
  {
    Error_Handler();
  }

}

static void MX_SPI3_Init(void)
{

  /* SPI3 parameter configuration*/
  hspi3.Instance = SPI3;
  hspi3.Init.Mode = SPI_MODE_SLAVE;
  hspi3.Init.Direction = SPI_DIRECTION_2LINES_RXONLY;
  hspi3.Init.DataSize = SPI_DATASIZE_16BIT;
  hspi3.Init.CLKPolarity = SPI_POLARITY_LOW;
  hspi3.Init.CLKPhase = SPI_PHASE_1EDGE;
  hspi3.Init.NSS = SPI_NSS_SOFT;
  hspi3.Init.FirstBit = SPI_FIRSTBIT_MSB;
  hspi3.Init.TIMode = SPI_TIMODE_DISABLE;
  hspi3.Init.CRCCalculation = SPI_CRCCALCULATION_DISABLE;
  hspi3.Init.CRCPolynomial = 7;
  hspi3.Init.CRCLength = SPI_CRC_LENGTH_DATASIZE;
  hspi3.Init.NSSPMode = SPI_NSS_PULSE_DISABLE;
  if (HAL_SPI_Init(&hspi3) != HAL_OK)
  {
    Error_Handler();
  }

}

static void MX_SPI4_Init(void)
{

  /* SPI4 parameter configuration*/
  hspi4.Instance = SPI4;
  hspi4.Init.Mode = SPI_MODE_SLAVE;
  hspi4.Init.Direction = SPI_DIRECTION_2LINES_RXONLY;
  hspi4.Init.DataSize = SPI_DATASIZE_16BIT;
  hspi4.Init.CLKPolarity = SPI_POLARITY_LOW;
  hspi4.Init.CLKPhase = SPI_PHASE_1EDGE;
  hspi4.Init.NSS = SPI_NSS_SOFT;
  hspi4.Init.FirstBit = SPI_FIRSTBIT_MSB;
  hspi4.Init.TIMode = SPI_TIMODE_DISABLE;
  hspi4.Init.CRCCalculation = SPI_CRCCALCULATION_DISABLE;
  hspi4.Init.CRCPolynomial = 7;
  hspi4.Init.CRCLength = SPI_CRC_LENGTH_DATASIZE;
  hspi4.Init.NSSPMode = SPI_NSS_PULSE_DISABLE;
  if (HAL_SPI_Init(&hspi4) != HAL_OK)
  {
    Error_Handler();
  }

}

static void MX_SPI5_Init(void)
{

  /* SPI5 parameter configuration*/
  hspi5.Instance = SPI5;
  hspi5.Init.Mode = SPI_MODE_SLAVE;
  hspi5.Init.Direction = SPI_DIRECTION_2LINES_RXONLY;
  hspi5.Init.DataSize = SPI_DATASIZE_16BIT;
  hspi5.Init.CLKPolarity = SPI_POLARITY_LOW;
  hspi5.Init.CLKPhase = SPI_PHASE_1EDGE;
  hspi5.Init.NSS = SPI_NSS_SOFT;
  hspi5.Init.FirstBit = SPI_FIRSTBIT_MSB;
  hspi5.Init.TIMode = SPI_TIMODE_DISABLE;
  hspi5.Init.CRCCalculation = SPI_CRCCALCULATION_DISABLE;
  hspi5.Init.CRCPolynomial = 7;
  hspi5.Init.CRCLength = SPI_CRC_LENGTH_DATASIZE;
  hspi5.Init.NSSPMode = SPI_NSS_PULSE_DISABLE;
  if (HAL_SPI_Init(&hspi5) != HAL_OK)
  {
    Error_Handler();
  }

}

static void MX_TIM1_Init(void)
{

  TIM_ClockConfigTypeDef sClockSourceConfig = {0};
  TIM_SlaveConfigTypeDef sSlaveConfig = {0};
  TIM_MasterConfigTypeDef sMasterConfig = {0};
  TIM_OC_InitTypeDef sConfigOC = {0};
  TIM_BreakDeadTimeConfigTypeDef sBreakDeadTimeConfig = {0};

  htim1.Instance = TIM1;
  htim1.Init.Prescaler = 0;
  htim1.Init.CounterMode = TIM_COUNTERMODE_UP;
  htim1.Init.Period = 0;
  htim1.Init.ClockDivision = TIM_CLOCKDIVISION_DIV1;
  htim1.Init.RepetitionCounter = 0;
  htim1.Init.AutoReloadPreload = TIM_AUTORELOAD_PRELOAD_DISABLE;
  if (HAL_TIM_Base_Init(&htim1) != HAL_OK)
  {
    Error_Handler();
  }
  sClockSourceConfig.ClockSource = TIM_CLOCKSOURCE_INTERNAL;
  if (HAL_TIM_ConfigClockSource(&htim1, &sClockSourceConfig) != HAL_OK)
  {
    Error_Handler();
  }
  if (HAL_TIM_OC_Init(&htim1) != HAL_OK)
  {
    Error_Handler();
  }
  sSlaveConfig.SlaveMode = TIM_SLAVEMODE_TRIGGER;
  sSlaveConfig.InputTrigger = TIM_TS_ETRF;
  sSlaveConfig.TriggerPolarity = TIM_TRIGGERPOLARITY_NONINVERTED;
  sSlaveConfig.TriggerPrescaler = TIM_TRIGGERPRESCALER_DIV1;
  sSlaveConfig.TriggerFilter = 0;
  if (HAL_TIM_SlaveConfigSynchro(&htim1, &sSlaveConfig) != HAL_OK)
  {
    Error_Handler();
  }
  sMasterConfig.MasterOutputTrigger = TIM_TRGO_RESET;
  sMasterConfig.MasterOutputTrigger2 = TIM_TRGO2_RESET;
  sMasterConfig.MasterSlaveMode = TIM_MASTERSLAVEMODE_DISABLE;
  if (HAL_TIMEx_MasterConfigSynchronization(&htim1, &sMasterConfig) != HAL_OK)
  {
    Error_Handler();
  }
  sConfigOC.OCMode = TIM_OCMODE_TIMING;
  sConfigOC.Pulse = 0;
  sConfigOC.OCPolarity = TIM_OCPOLARITY_HIGH;
  sConfigOC.OCNPolarity = TIM_OCNPOLARITY_HIGH;
  sConfigOC.OCFastMode = TIM_OCFAST_DISABLE;
  sConfigOC.OCIdleState = TIM_OCIDLESTATE_RESET;
  sConfigOC.OCNIdleState = TIM_OCNIDLESTATE_RESET;
  if (HAL_TIM_OC_ConfigChannel(&htim1, &sConfigOC, TIM_CHANNEL_1) != HAL_OK)
  {
    Error_Handler();
  }
  sBreakDeadTimeConfig.OffStateRunMode = TIM_OSSR_DISABLE;
  sBreakDeadTimeConfig.OffStateIDLEMode = TIM_OSSI_DISABLE;
  sBreakDeadTimeConfig.LockLevel = TIM_LOCKLEVEL_OFF;
  sBreakDeadTimeConfig.DeadTime = 0;
  sBreakDeadTimeConfig.BreakState = TIM_BREAK_DISABLE;
  sBreakDeadTimeConfig.BreakPolarity = TIM_BREAKPOLARITY_HIGH;
  sBreakDeadTimeConfig.BreakFilter = 0;
  sBreakDeadTimeConfig.Break2State = TIM_BREAK2_DISABLE;
  sBreakDeadTimeConfig.Break2Polarity = TIM_BREAK2POLARITY_HIGH;
  sBreakDeadTimeConfig.Break2Filter = 0;
  sBreakDeadTimeConfig.AutomaticOutput = TIM_AUTOMATICOUTPUT_DISABLE;
  if (HAL_TIMEx_ConfigBreakDeadTime(&htim1, &sBreakDeadTimeConfig) != HAL_OK)
  {
    Error_Handler();
  }
  HAL_TIM_MspPostInit(&htim1);

}

static void MX_TIM6_Init(void)
{

  TIM_MasterConfigTypeDef sMasterConfig = {0};

  htim6.Instance = TIM6;
  htim6.Init.Prescaler = 0;
  htim6.Init.CounterMode = TIM_COUNTERMODE_UP;
  htim6.Init.Period = 143;
  htim6.Init.AutoReloadPreload = TIM_AUTORELOAD_PRELOAD_ENABLE;
  if (HAL_TIM_Base_Init(&htim6) != HAL_OK)
  {
    Error_Handler();
  }
  sMasterConfig.MasterOutputTrigger = TIM_TRGO_UPDATE;
  sMasterConfig.MasterSlaveMode = TIM_MASTERSLAVEMODE_DISABLE;
  if (HAL_TIMEx_MasterConfigSynchronization(&htim6, &sMasterConfig) != HAL_OK)
  {
    Error_Handler();
  }

}

static void MX_TIM14_Init(void)
{

  htim14.Instance = TIM14;
  htim14.Init.Prescaler = 21599;
  htim14.Init.CounterMode = TIM_COUNTERMODE_UP;
  htim14.Init.Period = 1999;
  htim14.Init.ClockDivision = TIM_CLOCKDIVISION_DIV1;
  htim14.Init.AutoReloadPreload = TIM_AUTORELOAD_PRELOAD_ENABLE;
  if (HAL_TIM_Base_Init(&htim14) != HAL_OK)
  {
    Error_Handler();
  }

}

static void MX_UART4_Init(void)
{

  huart4.Instance = UART4;
  huart4.Init.BaudRate = 115200;
  huart4.Init.WordLength = UART_WORDLENGTH_8B;
  huart4.Init.StopBits = UART_STOPBITS_1;
  huart4.Init.Parity = UART_PARITY_NONE;
  huart4.Init.Mode = UART_MODE_TX_RX;
  huart4.Init.HwFlowCtl = UART_HWCONTROL_NONE;
  huart4.Init.OverSampling = UART_OVERSAMPLING_16;
  huart4.Init.OneBitSampling = UART_ONE_BIT_SAMPLE_DISABLE;
  huart4.AdvancedInit.AdvFeatureInit = UART_ADVFEATURE_NO_INIT;
  if (HAL_UART_Init(&huart4) != HAL_OK)
  {
    Error_Handler();
  }

}

static void MX_UART8_Init(void)
{

  huart8.Instance = UART8;
  huart8.Init.BaudRate = 115200;
  huart8.Init.WordLength = UART_WORDLENGTH_8B;
  huart8.Init.StopBits = UART_STOPBITS_1;
  huart8.Init.Parity = UART_PARITY_NONE;
  huart8.Init.Mode = UART_MODE_TX_RX;
  huart8.Init.HwFlowCtl = UART_HWCONTROL_NONE;
  huart8.Init.OverSampling = UART_OVERSAMPLING_16;
  huart8.Init.OneBitSampling = UART_ONE_BIT_SAMPLE_DISABLE;
  huart8.AdvancedInit.AdvFeatureInit = UART_ADVFEATURE_NO_INIT;
  if (HAL_UART_Init(&huart8) != HAL_OK)
  {
    Error_Handler();
  }

}

static void MX_USART1_UART_Init(void)
{

  huart1.Instance = USART1;
  huart1.Init.BaudRate = 2000000;
  huart1.Init.WordLength = UART_WORDLENGTH_8B;
  huart1.Init.StopBits = UART_STOPBITS_1;
  huart1.Init.Parity = UART_PARITY_NONE;
  huart1.Init.Mode = UART_MODE_TX_RX;
  huart1.Init.HwFlowCtl = UART_HWCONTROL_NONE;
  huart1.Init.OverSampling = UART_OVERSAMPLING_16;
  huart1.Init.OneBitSampling = UART_ONE_BIT_SAMPLE_DISABLE;
  huart1.AdvancedInit.AdvFeatureInit = UART_ADVFEATURE_RXOVERRUNDISABLE_INIT;
  huart1.AdvancedInit.OverrunDisable = UART_ADVFEATURE_OVERRUN_DISABLE;
  if (HAL_UART_Init(&huart1) != HAL_OK)
  {
    Error_Handler();
  }

}

static void MX_USART2_UART_Init(void)
{

  huart2.Instance = USART2;
  huart2.Init.BaudRate = 2000000;
  huart2.Init.WordLength = UART_WORDLENGTH_8B;
  huart2.Init.StopBits = UART_STOPBITS_1;
  huart2.Init.Parity = UART_PARITY_NONE;
  huart2.Init.Mode = UART_MODE_TX_RX;
  huart2.Init.HwFlowCtl = UART_HWCONTROL_NONE;
  huart2.Init.OverSampling = UART_OVERSAMPLING_16;
  huart2.Init.OneBitSampling = UART_ONE_BIT_SAMPLE_DISABLE;
  huart2.AdvancedInit.AdvFeatureInit = UART_ADVFEATURE_RXOVERRUNDISABLE_INIT;
  huart2.AdvancedInit.OverrunDisable = UART_ADVFEATURE_OVERRUN_DISABLE;
  if (HAL_UART_Init(&huart2) != HAL_OK)
  {
    Error_Handler();
  }

}

static void MX_USART3_UART_Init(void)
{

  huart3.Instance = USART3;
  huart3.Init.BaudRate = 2000000;
  huart3.Init.WordLength = UART_WORDLENGTH_8B;
  huart3.Init.StopBits = UART_STOPBITS_1;
  huart3.Init.Parity = UART_PARITY_NONE;
  huart3.Init.Mode = UART_MODE_TX_RX;
  huart3.Init.HwFlowCtl = UART_HWCONTROL_NONE;
  huart3.Init.OverSampling = UART_OVERSAMPLING_16;
  huart3.Init.OneBitSampling = UART_ONE_BIT_SAMPLE_DISABLE;
  huart3.AdvancedInit.AdvFeatureInit = UART_ADVFEATURE_RXOVERRUNDISABLE_INIT;
  huart3.AdvancedInit.OverrunDisable = UART_ADVFEATURE_OVERRUN_DISABLE;
  if (HAL_UART_Init(&huart3) != HAL_OK)
  {
    Error_Handler();
  }

}

static void MX_USART6_UART_Init(void)
{

  huart6.Instance = USART6;
  huart6.Init.BaudRate = 2000000;
  huart6.Init.WordLength = UART_WORDLENGTH_8B;
  huart6.Init.StopBits = UART_STOPBITS_1;
  huart6.Init.Parity = UART_PARITY_NONE;
  huart6.Init.Mode = UART_MODE_TX_RX;
  huart6.Init.HwFlowCtl = UART_HWCONTROL_NONE;
  huart6.Init.OverSampling = UART_OVERSAMPLING_16;
  huart6.Init.OneBitSampling = UART_ONE_BIT_SAMPLE_DISABLE;
  huart6.AdvancedInit.AdvFeatureInit = UART_ADVFEATURE_RXOVERRUNDISABLE_INIT;
  huart6.AdvancedInit.OverrunDisable = UART_ADVFEATURE_OVERRUN_DISABLE;
  if (HAL_UART_Init(&huart6) != HAL_OK)
  {
    Error_Handler();
  }

}

static void MX_DMA_Init(void)
{

  /* DMA controller clock enable */
  __HAL_RCC_DMA2_CLK_ENABLE();
  __HAL_RCC_DMA1_CLK_ENABLE();

  /* DMA interrupt init */
  /* DMA1_Stream1_IRQn interrupt configuration */
  HAL_NVIC_SetPriority(DMA1_Stream1_IRQn, 1, 0);
  HAL_NVIC_EnableIRQ(DMA1_Stream1_IRQn);
  /* DMA1_Stream5_IRQn interrupt configuration */
  HAL_NVIC_SetPriority(DMA1_Stream5_IRQn, 2, 0);
  HAL_NVIC_EnableIRQ(DMA1_Stream5_IRQn);
  /* DMA2_Stream0_IRQn interrupt configuration */
  HAL_NVIC_SetPriority(DMA2_Stream0_IRQn, 2, 0);
  HAL_NVIC_EnableIRQ(DMA2_Stream0_IRQn);
  /* DMA2_Stream1_IRQn interrupt configuration */
  HAL_NVIC_SetPriority(DMA2_Stream1_IRQn, 3, 0);
  HAL_NVIC_EnableIRQ(DMA2_Stream1_IRQn);
  /* DMA2_Stream2_IRQn interrupt configuration */
  HAL_NVIC_SetPriority(DMA2_Stream2_IRQn, 4, 0);
  HAL_NVIC_EnableIRQ(DMA2_Stream2_IRQn);

}

/* FMC initialization function */
static void MX_FMC_Init(void)
{

  FMC_SDRAM_TimingTypeDef SdramTiming = {0};

  /** Perform the SDRAM1 memory initialization sequence
  */
  hsdram1.Instance = FMC_SDRAM_DEVICE;
  /* hsdram1.Init */
  hsdram1.Init.SDBank = FMC_SDRAM_BANK2;
  hsdram1.Init.ColumnBitsNumber = FMC_SDRAM_COLUMN_BITS_NUM_10;
  hsdram1.Init.RowBitsNumber = FMC_SDRAM_ROW_BITS_NUM_13;
  hsdram1.Init.MemoryDataWidth = FMC_SDRAM_MEM_BUS_WIDTH_8;
  hsdram1.Init.InternalBankNumber = FMC_SDRAM_INTERN_BANKS_NUM_4;
  hsdram1.Init.CASLatency = FMC_SDRAM_CAS_LATENCY_2;
  hsdram1.Init.WriteProtection = FMC_SDRAM_WRITE_PROTECTION_DISABLE;
  hsdram1.Init.SDClockPeriod = FMC_SDRAM_CLOCK_DISABLE;
  hsdram1.Init.ReadBurst = FMC_SDRAM_RBURST_DISABLE;
  hsdram1.Init.ReadPipeDelay = FMC_SDRAM_RPIPE_DELAY_0;
  /* SdramTiming */
  SdramTiming.LoadToActiveDelay = 16;
  SdramTiming.ExitSelfRefreshDelay = 16;
  SdramTiming.SelfRefreshTime = 16;
  SdramTiming.RowCycleDelay = 16;
  SdramTiming.WriteRecoveryTime = 16;
  SdramTiming.RPDelay = 16;
  SdramTiming.RCDDelay = 16;

  if (HAL_SDRAM_Init(&hsdram1, &SdramTiming) != HAL_OK)
  {
    Error_Handler( );
  }

}

static void MX_GPIO_Init(void)
{
  GPIO_InitTypeDef GPIO_InitStruct = {0};

  /* GPIO Ports Clock Enable */
  __HAL_RCC_GPIOE_CLK_ENABLE();
  __HAL_RCC_GPIOC_CLK_ENABLE();
  __HAL_RCC_GPIOF_CLK_ENABLE();
  __HAL_RCC_GPIOH_CLK_ENABLE();
  __HAL_RCC_GPIOA_CLK_ENABLE();
  __HAL_RCC_GPIOB_CLK_ENABLE();
  __HAL_RCC_GPIOG_CLK_ENABLE();
  __HAL_RCC_GPIOD_CLK_ENABLE();

  /*Configure GPIO pin Output Level */
  HAL_GPIO_WritePin(GPIOC, HJ_MODE_Pin|GPIO_PIN_14|HJ_STATE_Pin|LED_BUF_75_Pin
                          |LED_BUF_50_Pin, GPIO_PIN_RESET);

  /*Configure GPIO pin Output Level */
  HAL_GPIO_WritePin(BLE_LED_GPIO_Port, BLE_LED_Pin, GPIO_PIN_RESET);

  /*Configure GPIO pin Output Level */
  HAL_GPIO_WritePin(LED_BUF_100_GPIO_Port, LED_BUF_100_Pin, GPIO_PIN_RESET);

  /*Configure GPIO pin Output Level */
  HAL_GPIO_WritePin(GPIOB, LED_BUF_25_Pin|VEE_IC_EN_Pin|VEE_EN_Pin|VCC_EN_Pin
                          |GPIO_PIN_9, GPIO_PIN_RESET);

  /*Configure GPIO pin Output Level */
  HAL_GPIO_WritePin(NBL_0_GPIO_Port, NBL_0_Pin, GPIO_PIN_SET);

  /*Configure GPIO pin Output Level */
  HAL_GPIO_WritePin(GPIOD, MODE4_LED_Pin|MODE3_LED_Pin|MODE2_LED_Pin|MODE1_LED_Pin
                          |SD_LED_Pin, GPIO_PIN_RESET);

  /*Configure GPIO pins : HJ_MODE_Pin PC14 HJ_STATE_Pin LED_BUF_75_Pin
                           LED_BUF_50_Pin */
  GPIO_InitStruct.Pin = HJ_MODE_Pin|GPIO_PIN_14|HJ_STATE_Pin|LED_BUF_75_Pin
                          |LED_BUF_50_Pin;
  GPIO_InitStruct.Mode = GPIO_MODE_OUTPUT_PP;
  GPIO_InitStruct.Pull = GPIO_NOPULL;
  GPIO_InitStruct.Speed = GPIO_SPEED_FREQ_LOW;
  HAL_GPIO_Init(GPIOC, &GPIO_InitStruct);

  /*Configure GPIO pin : BLE_LED_Pin */
  GPIO_InitStruct.Pin = BLE_LED_Pin;
  GPIO_InitStruct.Mode = GPIO_MODE_OUTPUT_PP;
  GPIO_InitStruct.Pull = GPIO_NOPULL;
  GPIO_InitStruct.Speed = GPIO_SPEED_FREQ_LOW;
  HAL_GPIO_Init(BLE_LED_GPIO_Port, &GPIO_InitStruct);

  /*Configure GPIO pin : LED_BUF_100_Pin */
  GPIO_InitStruct.Pin = LED_BUF_100_Pin;
  GPIO_InitStruct.Mode = GPIO_MODE_OUTPUT_PP;
  GPIO_InitStruct.Pull = GPIO_NOPULL;
  GPIO_InitStruct.Speed = GPIO_SPEED_FREQ_LOW;
  HAL_GPIO_Init(LED_BUF_100_GPIO_Port, &GPIO_InitStruct);

  /*Configure GPIO pins : LED_BUF_25_Pin VEE_IC_EN_Pin VEE_EN_Pin VCC_EN_Pin
                           PB9 */
  GPIO_InitStruct.Pin = LED_BUF_25_Pin|VEE_IC_EN_Pin|VEE_EN_Pin|VCC_EN_Pin
                          |GPIO_PIN_9;
  GPIO_InitStruct.Mode = GPIO_MODE_OUTPUT_PP;
  GPIO_InitStruct.Pull = GPIO_NOPULL;
  GPIO_InitStruct.Speed = GPIO_SPEED_FREQ_LOW;
  HAL_GPIO_Init(GPIOB, &GPIO_InitStruct);

  /*Configure GPIO pin : NBL_0_Pin */
  GPIO_InitStruct.Pin = NBL_0_Pin;
  GPIO_InitStruct.Mode = GPIO_MODE_OUTPUT_PP;
  GPIO_InitStruct.Pull = GPIO_NOPULL;
  GPIO_InitStruct.Speed = GPIO_SPEED_FREQ_VERY_HIGH;
  HAL_GPIO_Init(NBL_0_GPIO_Port, &GPIO_InitStruct);

  /*Configure GPIO pins : MODE4_LED_Pin MODE3_LED_Pin MODE2_LED_Pin MODE1_LED_Pin
                           SD_LED_Pin */
  GPIO_InitStruct.Pin = MODE4_LED_Pin|MODE3_LED_Pin|MODE2_LED_Pin|MODE1_LED_Pin
                          |SD_LED_Pin;
  GPIO_InitStruct.Mode = GPIO_MODE_OUTPUT_PP;
  GPIO_InitStruct.Pull = GPIO_NOPULL;
  GPIO_InitStruct.Speed = GPIO_SPEED_FREQ_LOW;
  HAL_GPIO_Init(GPIOD, &GPIO_InitStruct);

}

/* USER CODE BEGIN 4 */
void PowerUp_IC()
{
	//Enable Power
	HAL_GPIO_WritePin(VCC_EN_GPIO_Port,VCC_EN_Pin,GPIO_PIN_SET);	//Power Up intan
	HAL_GPIO_WritePin(VEE_IC_EN_GPIO_Port,VEE_IC_EN_Pin,GPIO_PIN_SET);	//Power up IC transiver
	HAL_GPIO_WritePin(VEE_EN_GPIO_Port,VEE_EN_Pin,GPIO_PIN_RESET); //Disable LVDS transiver
}
void Init_Buffer()
{
	dataMGR_init(&MGR_TX,(char*) data_buf_TX,sizeof(data_buf_TX));						//FIFO setup
	dataMGR_init(&MGR_RX1,(char*) data_buf_RX1,sizeof(data_buf_RX1));					//RX FIFO setup
	dataMGR_init(&MGR_RX2,(char*) data_buf_RX2,sizeof(data_buf_RX2));					//RX FIFO setup
	dataMGR_init(&MGR_RX3,(char*) data_buf_RX3,sizeof(data_buf_RX3));					//RX FIFO setup
	dataMGR_init(&MGR_RX4,(char*) data_buf_RX4,sizeof(data_buf_RX4));					//RX FIFO setup
	dataMGR_init(&MGR_CDC,(char*) data_buf_RX_CDC,sizeof(data_buf_RX_CDC));		//RX FIFO setup
}

void Init_Ioncom_Receiver()
{
	IC_handle1.DMA_TotalBanks=4;
	IC_handle1.DMA_TransSize=BUF_SIZE/IC_handle1.DMA_TotalBanks;
	IC_handle1.huart=&huart1;
	IC_handle1.IRQn=USART1_IRQn;
	IC_handle1.huart->hdmarx->Instance=DMA2_Stream2;
	IC_handle1.config|=(IONCOM_CONFIG_RXDMA);
	CE32_Ioncom_Init(&IC_handle1,(char*)data_buf_RX1,sizeof(data_buf_RX1),(char*)data_buf_TX,(uint16_t)sizeof(data_buf_TX));
	UART_IONCOM_DMA_Init(&IC_handle1);
	UART_DISABLE(IC_handle1.huart->Instance);					//Disable UART temporarly to avoid interferece with initialization
	IC_handle1.huart->hdmarx->Instance->M0AR = (uint32_t)IC_handle1.RX_MGR.dataPtr; //Set the DMA to be in circular mode and automatic filling the buffer
	IC_handle1.huart->hdmarx->Instance->NDTR = IC_handle1.RX_MGR.dataSize;

	IC_handle2.DMA_TotalBanks=4;
	IC_handle2.DMA_TransSize=BUF_SIZE/IC_handle2.DMA_TotalBanks;
	IC_handle2.huart=&huart2;
	IC_handle2.IRQn=USART2_IRQn;
	IC_handle2.huart->hdmarx->Instance=DMA1_Stream5;
	IC_handle2.config|=(IONCOM_CONFIG_RXDMA);
	CE32_Ioncom_Init(&IC_handle2,(char*)data_buf_RX2,sizeof(data_buf_RX2),(char*)data_buf_TX,(uint16_t)sizeof(data_buf_TX));
	UART_IONCOM_DMA_Init(&IC_handle2);
	UART_DISABLE(IC_handle2.huart->Instance);					//Disable UART temporarly to avoid interferece with initialization
	IC_handle2.huart->hdmarx->Instance->M0AR = (uint32_t)IC_handle2.RX_MGR.dataPtr; //Set the DMA to be in circular mode and automatic filling the buffer
	IC_handle2.huart->hdmarx->Instance->NDTR = IC_handle2.RX_MGR.dataSize/4;

	IC_handle3.DMA_TotalBanks=4;
	IC_handle3.DMA_TransSize=BUF_SIZE/IC_handle3.DMA_TotalBanks;
	IC_handle3.huart=&huart3;
	IC_handle3.IRQn=USART3_IRQn;
	IC_handle3.huart->hdmarx->Instance=DMA1_Stream1;
	IC_handle3.config|=(IONCOM_CONFIG_RXDMA);
	CE32_Ioncom_Init(&IC_handle3,(char*)data_buf_RX3,sizeof(data_buf_RX3),(char*)data_buf_TX,(uint16_t)sizeof(data_buf_TX));
	UART_IONCOM_DMA_Init(&IC_handle3);
	UART_DISABLE(IC_handle3.huart->Instance);					//Disable UART temporarly to avoid interferece with initialization
	IC_handle3.huart->hdmarx->Instance->M0AR = (uint32_t)IC_handle3.RX_MGR.dataPtr; //Set the DMA to be in circular mode and automatic filling the buffer
	IC_handle3.huart->hdmarx->Instance->NDTR = IC_handle3.RX_MGR.dataSize/4;

	IC_handle4.DMA_TotalBanks=4;
	IC_handle4.DMA_TransSize=BUF_SIZE/IC_handle4.DMA_TotalBanks;
	IC_handle4.huart=&huart6;
	IC_handle4.IRQn=USART6_IRQn;
	IC_handle4.huart->hdmarx->Instance=DMA2_Stream1;
	IC_handle4.config|=(IONCOM_CONFIG_RXDMA);
	CE32_Ioncom_Init(&IC_handle4,(char*)data_buf_RX4,sizeof(data_buf_RX4),(char*)data_buf_TX,(uint16_t)sizeof(data_buf_TX));
	UART_IONCOM_DMA_Init(&IC_handle4);
	UART_DISABLE(IC_handle4.huart->Instance);					//Disable UART temporarly to avoid interferece with initialization
	IC_handle4.huart->hdmarx->Instance->M0AR = (uint32_t)IC_handle4.RX_MGR.dataPtr; //Set the DMA to be in circular mode and automatic filling the buffer
	IC_handle4.huart->hdmarx->Instance->NDTR = IC_handle4.RX_MGR.dataSize/4;
	//UART7->CR1|=USART_CR1_RXNEIE;  //Enable RX interrput to receive commands
}

void RXdata_Indicator_Init()
{
	TIM14->CR1|=TIM_CR1_CEN;	//Enable timer
	TIM14->DIER|=TIM_DIER_UIE;//Enable update interrupt
}

void RX_processor(CE32_IONCOM_Handle *IC_handle,int CH)
{
	if(IC_handle->RX_MGR.bufferUsed[0]>=144)
		{
			dataMGR_enQueue_byte(&MGR_CDC,0x66);
			dataMGR_enQueue_byte(&MGR_CDC,0x55);
			dataMGR_enQueue_byte(&MGR_CDC,0x5d);
			dataMGR_enQueue_byte(&MGR_CDC,CH);
			for(int i=0;i<144;i++)
			{
				//dataMGR_enQueue_byte(&MGR_CDC,0xAA);
				uint8_t temp=(uint8_t)dataMGR_deQueue_byte(&IC_handle->RX_MGR,0);
//								if(temp==0)
//								{
//									__nop();
//								}
				dataMGR_enQueue_byte(&MGR_CDC,temp);
			}

			//break;

		}
}

void USB_SEND()
{
	const uint16_t ByteToSend = 2048;
	if(MGR_CDC.bufferUsed[0]>=ByteToSend)
	{
		if(CDC_Transmit_HS((uint8_t*)(data_buf_RX_CDC+MGR_CDC.outPTR[0]),ByteToSend)==USBD_OK)
		{
			dataMGR_deQueue(&MGR_CDC,ByteToSend,0);

			//__HAL_TIM_DISABLE(&htim6);
		}
	}
}
/* USER CODE END 4 */

void Error_Handler(void)
{
}

/************************ (C) COPYRIGHT STMicroelectronics *****END OF FILE****/
